# nrf9120_mlm1_modem register map
Vendor: Nordic Semiconductor; Series: nrf91; File version: 1
CPU: CM4 r0p1, little endian, MPU, no FPU, 3 interrupt priority bits
Registers are 32-bit, read-write, reset 0x0 unless marked. A register's access mark holds for its fields unless they carry their own. Offsets are from the block's base; [hi:lo] are bit positions; lines under a group give offsets from that group; {n}, {i} and the like mark numbered series.

## FICR — Factory Information Configuration Registers
Base 0x00FF0000
0x100 TESTSTATUS ro reset 0xFFFFFFFF — Code memory test status. Will be set during production test.
0x104 CPTEST0 ro reset 0xFFFFFFFF — Result from Circuit Probe test
  [31:0] CP1
0x108 CPTEST00 ro reset 0xFFFFFFFF — Result from Circuit Probe test
  [31:0] CP2
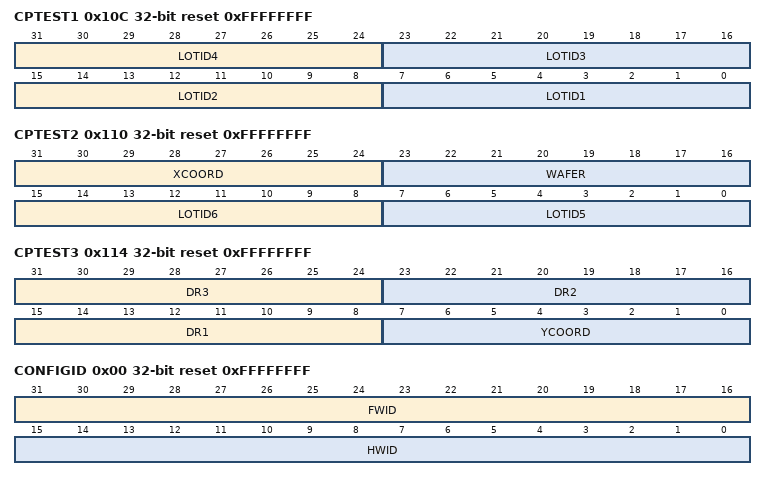
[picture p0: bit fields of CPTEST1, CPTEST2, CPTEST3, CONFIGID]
0x10C CPTEST1 ro reset 0xFFFFFFFF — Result from Circuit Probe test
  [31:24] LOTID4 — 4th ascii byte of Lot ID character
  [23:16] LOTID3 — 3rd ascii byte of Lot ID character
  [15:8] LOTID2 — 2nd ascii byte of Lot ID character
  [7:0] LOTID1 — 1st ascii byte of Lot ID character
0x110 CPTEST2 ro reset 0xFFFFFFFF — Result from Circuit Probe test
  [31:24] XCOORD — Device X-coordinate, always >=0, offset so that the leftmost value on wafer is 0
  [23:16] WAFER — Wafer number, 1 byte integer
  [15:8] LOTID6 — 6th ascii byte of Lot ID character
  [7:0] LOTID5 — 5th ascii byte of Lot ID character
0x114 CPTEST3 ro reset 0xFFFFFFFF — Result from Circuit Probe test
  [31:24] DR3 — Data Retention (DR) flag
  [23:16] DR2 — Data Retention (DR) flag
  [15:8] DR1 — Data Retention (DR) flag
  [7:0] YCOORD — Device Y-coordinate, always >=0, offset so that the bottom value on wafer is 0
0x118 CPTEST4 ro reset 0xFFFFFFFF — Result from Circuit Probe test
  [7:0] DR4 — Data Retention (DR) flag
{0x108+4i} CPTEST{i} ro reset 0xFFFFFFFF (i=5..8) — Result from Circuit Probe test, flash repair information
  [31:0] CPTEST{i} — flash repair information
0x200 INFO group — Device info
  0x00 CONFIGID ro reset 0xFFFFFFFF — Configuration identifier
    [31:16] FWID — Deprecated field - Identification number for the FW that is pre-loaded into the chip
    [15:0] HWID — Identification number for the HW
  {0x4+4j} DEVICEID[{j}] (j=0..1) ro reset 0xFFFFFFFF — Description collection: Device identifier
    [31:0] DEVICEID — 64 bit unique device identifier
  0x0C PART ro reset 0x52832 — Part code
    [31:0] PART
      0xFFFFFFFF=Unspecified
  0x10 VARIANT ro reset 0x41414142 — Part Variant, Hardware version and Production configuration
    [31:0] VARIANT — Part Variant, Hardware version and Production configuration, encoded as ASCII
      0xFFFFFFFF=Unspecified
  0x14 PACKAGE ro reset 0x2000 — Package option
    [31:0] PACKAGE
      0xFFFFFFFF=Unspecified
  0x18 RAM ro reset 0x40 — RAM variant
    [31:0] RAM
      0xFFFFFFFF=Unspecified
  0x1C FLASH ro reset 0x200 — Flash variant
    [31:0] FLASH
      0xFFFFFFFF=Unspecified
  0x20 CODEPAGESIZE ro reset 0xFFFFFFFF — Code memory page size
  0x24 CODESIZE ro reset 0xFFFFFFFF — Code memory size
    [31:0] CODESIZE — Code memory size in number of pages
  0x28 DEVICETYPE ro reset 0xFFFFFFFF
    [31:0] DEVICETYPE
      0=Die (Device is an physical DIE); 0xFFFFFFFF=FPGA (Device is an FPGA)
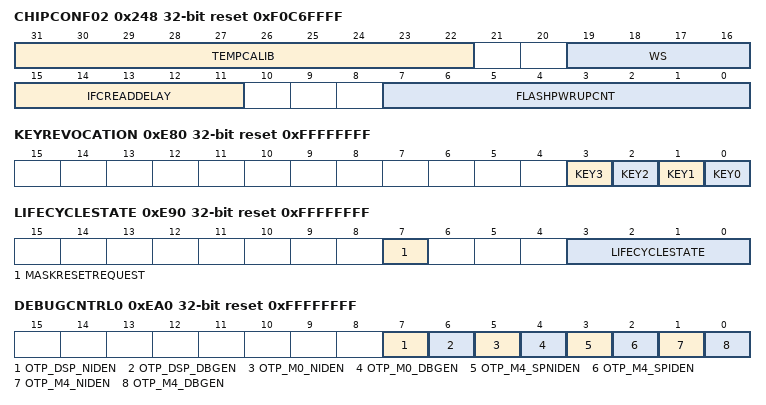
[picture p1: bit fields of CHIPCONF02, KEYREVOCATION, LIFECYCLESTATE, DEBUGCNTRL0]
0x248 CHIPCONF02 ro reset 0xF0C6FFFF — Miscellaneous analog configuration. Will be set during production test.
  [31:22] TEMPCALIB — TEMP module calibration value (default value for TEMP->CALIB)
  [19:16] WS — wait-states (excluding the cache controller) for I-Code flash access, D-Code has one more wait-state.
    {v}={v}WS ({v} wait-state in total for I-Code ({v+1} for D-Code)) (v=1..15)
  [15:11] IFCREADDELAY — number of cycles before Information Configuration Registers can be read
  [7:0] FLASHPWRUPCNT — Number of successful FLASHPWRUPn read cycles when powering up flash. After chip power up, the NVMC controller reads FLASHPWRUPn for 7 us.
0x280 FLASHPWRUP0 ro reset 0xAAAAAAAA — Power-up pattern for flash
0x284 FLASHPWRUP1 ro reset 0xAAAAAAAA — Power-up pattern for flash
{0x300+8i} TRIMCNF[{i}] (i=0..4) group — Unspecified
  0x00 ADDR ro — Description cluster: Address
    [31:0] Address
  0x04 DATA ro — Description cluster: Data
{0x800+4i} PRODTEST[{i}] (i=0..2) ro reset 0xFFFFFFFF — Description collection: Production test control n
  [31:0] PRODTEST — Production test control (majority vote done for each bit over all three fields to get the used value)
    0xBB42319F=Done (Production tests done); 0xFFFFFFFF=NotDone (Production tests not done, SoC is in Virgin mode (with any other value than 0xBB42319F))
0x80C BPROTINIT ro reset 0xFFFFFFFF — BPROT initialization data
  [31:0] BPROTINIT — BPROT CONFIG0 initialization data, covering 32 lowest 4kbyte blocks of Flash
{0x810+4i} PUBLICID[{i}] (i=0..3) ro reset 0xFFFFFFFF — Description collection: Public ID n
  [31:0] PUBLICID — Public ID (32 bits of a 128 bit field)
{0x820+4i} ROOTKEY0[{i}] (i=0..67) ro reset 0xFFFFFFFF — Description collection: Root public key 0, total length 2176 bits = 272 bytes (end address is 0x92F)
{0x930+4i} ROOTKEY1[{i}] (i=0..67) ro reset 0xFFFFFFFF — Description collection: Root public key 1, total length 2176 bits = 272 bytes (end address is 0xA3F)
{0xA40+4i} ROOTKEY2[{i}] (i=0..67) ro reset 0xFFFFFFFF — Description collection: Root public key 2, total length 2176 bits = 272 bytes (end address is 0xB4F)
{0xB50+4i} ROOTKEY3[{i}] (i=0..67) ro reset 0xFFFFFFFF — Description collection: Root public key 3, total length 2176 bits = 272 bytes (end address is 0xC5F)
{0xC60+4i} IMEI[{i}] (i=0..1) ro reset 0xFFFFFFFF — Description collection: IMEI n
  [31:0] IMEI — IMEI in BCD decoded nibbles
{0xC68+4i} MAC0[{i}] (i=0..1) ro reset 0xFFFFFFFF — Description collection: MAC0 n
  [31:0] MAC0 — MAC0 value
{0xC70+4i} MAC1[{i}] (i=0..1) ro reset 0xFFFFFFFF — Description collection: MAC1 n
  [31:0] MAC1 — MAC1 value
{0xC78+4i} MAC2[{i}] (i=0..1) ro reset 0xFFFFFFFF — Description collection: MAC2 n
  [31:0] MAC2 — MAC2 value
{0xC80+4i} MAC3[{i}] (i=0..1) ro reset 0xFFFFFFFF — Description collection: MAC3 n
  [31:0] MAC3 — MAC3 value
{0xC90+4i} DEVCONF[{i}] (i=0..3) ro reset 0xFFFFFFFF — Description collection: Device configuration n
  [31:0] DEVCONF — Device configuration data, contents defined in SW
0xD80 DOWNGRADEPREV ro reset 0xFFFFFFFF — Downgrade prevention control. Totally 128 bits within 256 bytes, located in groups of 8 bits per 128 bit word (distributed due to Flash write count limit)
  [7:0] DOWNGRADEPREV — Downgrade prevention control bits
0xE80 KEYREVOCATION ro reset 0xFFFFFFFF — Key revocation control
  [all] fields
    1=Enabled (Key enabled); 0=Disabled (Key disabled)
  [3] KEY3 — Root key 3 (this key shall always be enabled, regardless of the value)
  [2] KEY2 — Root key 2
  [1] KEY1 — Root key 1
  [0] KEY0 — Root key 0
0xE90 LIFECYCLESTATE ro reset 0xFFFFFFFF — Lifecycle state [7:0]
  [7] MASKRESETREQUEST — Secure Control reset request mask
    1=Enabled (Reset request mask enabled); 0=Disabled (Reset request mask disabled)
  [3:0] LIFECYCLESTATE
    15=VIR (Virgin chip (b'1111)); 14=MF (Manufactured chip (b'1110)); 12=SEC (Secure chip (b'110X)); 11=RD (R&D chip (b'1011)); 4=FFR (Field failure return chip (b'01XX)); 0=DIS (Disabled chip (Other bit combinations))
0xEA0 DEBUGCNTRL0 ro reset 0xFFFFFFFF — Debug control bits [7:0]
  [7] OTP_DSP_NIDEN — DSP non-invasive debug control
    1=Enabled (Debug enabled (DSP NIDEN=1)); 0=Disabled (Debug disabled (DSP NIDEN=0))
  [6] OTP_DSP_DBGEN — DSP invasive debug control
    1=Enabled (Debug enabled (DSP DBGEN=1)); 0=Disabled (Debug disabled (DSP DBGEN=0))
  [5] OTP_M0_NIDEN — M0 non-invasive debug control
    1=Enabled (Debug enabled (M0 NIDEN=1)); 0=Disabled (Debug disabled (M0 NIDEN=0))
  [4] OTP_M0_DBGEN — M0 invasive debug control
    1=Enabled (Debug enabled (M0 DBGEN=1)); 0=Disabled (Debug disabled (M0 DBGEN=0))
  [3] OTP_M4_SPNIDEN — M4 secure non-invasive debug control
    1=Enabled (Secure debug enabled (M4 NIDEN=1 while M4 is in secure mode)); 0=Disabled (Secure debug disabled (M4 NIDEN=0 while M4 is in secure mode))
  [2] OTP_M4_SPIDEN — M4 secure invasive debug control
    1=Enabled (Secure debug enabled (M4 DBGEN=1 while M4 is in secure mode)); 0=Disabled (Secure debug disabled (M4 DBGEN=0 while M4 is in secure mode))
  [1] OTP_M4_NIDEN — M4 non-invasive debug control
    1=Enabled (Debug enabled (M4 NIDEN=1)); 0=Disabled (Debug disabled (M4 NIDEN=0))
  [0] OTP_M4_DBGEN — M4 invasive debug control
    1=Enabled (Debug enabled (M4 DBGEN=1)); 0=Disabled (Debug disabled (M4 DBGEN=0))
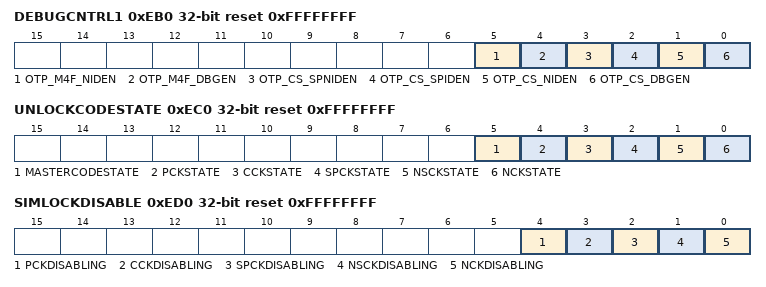
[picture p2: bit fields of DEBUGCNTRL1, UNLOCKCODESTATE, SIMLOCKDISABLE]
0xEB0 DEBUGCNTRL1 ro reset 0xFFFFFFFF — Debug control bits [13:8]
  [5] OTP_M4F_NIDEN — M4F non-invasive debug control
    1=Enabled (Debug enabled (M4F NIDEN=1)); 0=Disabled (Debug disabled (M4F NIDEN=0))
  [4] OTP_M4F_DBGEN — M4F invasive debug control
    1=Enabled (Debug enabled (M4F DBGEN=1)); 0=Disabled (Debug disabled (M4F DBGEN=0))
  [3] OTP_CS_SPNIDEN — Coresight secure non-invasive debug control
    1=Enabled (Secure debug enabled (Coresight SPNIDEN=1)); 0=Disabled (Secure debug disabled (Coresight SPNIDEN=0))
  [2] OTP_CS_SPIDEN — Coresight secure invasive debug control
    1=Enabled (Secure debug enabled (Coresight SPIDEN=1)); 0=Disabled (Secure debug disabled (Coresight SPIDEN=0))
  [1] OTP_CS_NIDEN — Coresight non-invasive debug control
    1=Enabled (Debug enabled (Coresight NIDEN=1)); 0=Disabled (Debug disabled (Coresight NIDEN=0))
  [0] OTP_CS_DBGEN — Coresight invasive debug control
    1=Enabled (Debug enabled (Coresight DBGEN=1)); 0=Disabled (Debug disabled (Coresight DBGEN=0))
0xEC0 UNLOCKCODESTATE ro reset 0xFFFFFFFF — SIM unlock code state for each lock level
  [all] fields
    0=Active (Unlock code activated); 1=NotActive (Unlock code not activated)
  [5] MASTERCODESTATE — State of master unlock code
  [4] PCKSTATE — State of SIM/USIM unlock code
  [3] CCKSTATE — State of corporate unlock code
  [2] SPCKSTATE — State of service provider unlock code
  [1] NSCKSTATE — State of network subset unlock code
  [0] NCKSTATE — State of network unlock code
0xED0 SIMLOCKDISABLE ro reset 0xFFFFFFFF — SIM lock controls for each lock level. Disabling removes lock permanently
  [all] fields
    0=Disabled (Lock disabled); 1=NotDisabled (Lock not disabled)
  [4] PCKDISABLING — SIM/USIM lock control
  [3] CCKDISABLING — Corporate lock control
  [2] SPCKDISABLING — Service provider lock control
  [1] NSCKDISABLING — Network subset lock control
  [0] NCKDISABLING — Network lock control
{0xFC0+4i} SECMASTERKEY[{i}] (i=0..3) ro reset 0xFFFFFFFF — Description collection: Secure master key n
  [31:0] SECMASTERKEY — Unique secure master key, word n, readable only by HW
